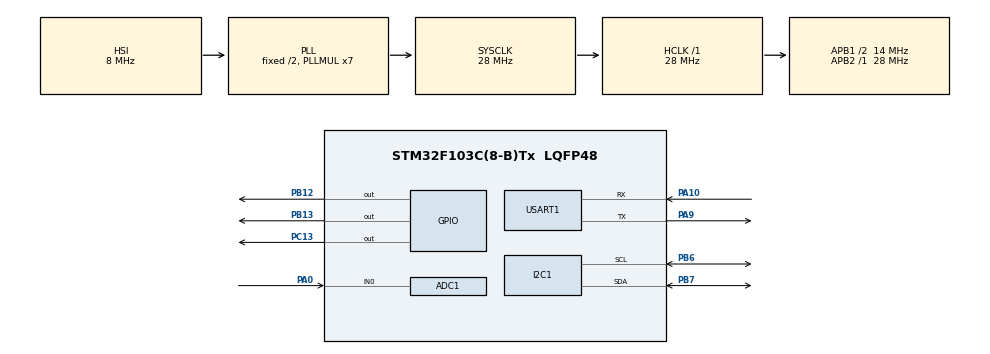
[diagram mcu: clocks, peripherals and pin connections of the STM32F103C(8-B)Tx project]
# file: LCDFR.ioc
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ADC1.Channel-2\#ChannelRegularConversion=ADC_CHANNEL_0
ADC1.NbrOfConversionFlag=1
ADC1.Rank-2\#ChannelRegularConversion=1
ADC1.SamplingTime-2\#ChannelRegularConversion=ADC_SAMPLETIME_239CYCLES_5
ADC1.master=1
Dma.ADC1.0.Direction=DMA_PERIPH_TO_MEMORY
Dma.ADC1.0.Instance=DMA1_Channel1
Dma.ADC1.0.MemDataAlignment=DMA_MDATAALIGN_WORD
Dma.ADC1.0.MemInc=DMA_MINC_ENABLE
Dma.ADC1.0.Mode=DMA_CIRCULAR
Dma.ADC1.0.PeriphDataAlignment=DMA_PDATAALIGN_WORD
Dma.ADC1.0.PeriphInc=DMA_PINC_DISABLE
Dma.ADC1.0.Priority=DMA_PRIORITY_LOW
Dma.Request0=ADC1
FREERTOS.Mutexes01=uartMutex,Dynamic,NULL
FREERTOS.Tasks01=TaskTemp,0,128,TaskTemp_init,Default,NULL,Dynamic,NULL,NULL;Task2,-3,128,Task2_init,Default,NULL,Dynamic,NULL,NULL
Mcu.Family=STM32F1
Mcu.Name=STM32F103C(8-B)Tx
Mcu.Package=LQFP48
NVIC.DMA1_Channel1_IRQn=true\:5\:0\:false\:false\:true\:true\:false\:true
NVIC.PriorityGroup=NVIC_PRIORITYGROUP_4
NVIC.TIM1_UP_IRQn=true\:0\:0\:false\:false\:true\:false\:false\:true
NVIC.TimeBase=TIM1_UP_IRQn
NVIC.TimeBaseIP=TIM1
PA0-WKUP.Signal=ADCx_IN0
PA10.Mode=Asynchronous
PA10.Signal=USART1_RX
PA13.Mode=Serial_Wire
PA13.Signal=SYS_JTMS-SWDIO
PA14.Mode=Serial_Wire
PA14.Signal=SYS_JTCK-SWCLK
PA9.Mode=Asynchronous
PA9.Signal=USART1_TX
PB12.Signal=GPIO_Output
PB13.Signal=GPIO_Output
PB6.Mode=I2C
PB6.Signal=I2C1_SCL
PB7.Mode=I2C
PB7.Signal=I2C1_SDA
PC13-TAMPER-RTC.Signal=GPIO_Output
ProjectManager.HeapSize=0x200
ProjectManager.StackSize=0x400
ProjectManager.TargetToolchain=STM32CubeIDE
RCC.AHBFreq_Value=28000000
RCC.APB1CLKDivider=RCC_HCLK_DIV2
RCC.APB1Freq_Value=14000000
RCC.APB1TimFreq_Value=28000000
RCC.APB2Freq_Value=28000000
RCC.APB2TimFreq_Value=28000000
RCC.HCLKFreq_Value=28000000
RCC.PLLMUL=RCC_PLL_MUL7
RCC.SYSCLKFreq_VALUE=28000000
RCC.SYSCLKSource=RCC_SYSCLKSOURCE_PLLCLK
RCC.USBFreq_Value=28000000
SH.ADCx_IN0.0=ADC1_IN0,IN0
USART1.VirtualMode=VM_ASYNC
VP_FREERTOS_VS_CMSIS_V1.Mode=CMSIS_V1
VP_SYS_VS_tim1.Mode=TIM1
board=custom

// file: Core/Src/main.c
/************************************************************************
* Copyright 2020 ITESM                                                  *
*                                                                       *
*                                                                       *
* Second Partial Project                                                *
*                                                                       *
* Authors:                                                              *
* Jesús Enrique Luna Medina          A01632334                          *
* Daniela abigail Parrales Mejía     A01228629                          *
* Luis Cortés Leal                   A01631163                          *
*                                                                       *
* May  2020                                                             *
*                                                                       *
* This is a temperature sensor that reports in serial port (UART)		*
* and in a 16x2 LCD I2C													*
*                                                                       *
************************************************************************/
#include "main.h"
#include "cmsis_os.h"

/* USER CODE BEGIN Includes */
#include "i2c-lcd.h"
/* USER CODE END Includes */

ADC_HandleTypeDef hadc1;
DMA_HandleTypeDef hdma_adc1;

I2C_HandleTypeDef hi2c1;

UART_HandleTypeDef huart1;

osThreadId TaskTempHandle;
osThreadId Task_ToggleHandle;
osMutexId uartMutexHandle;
osThreadId Task_LCDHandle;

void SystemClock_Config(void);
static void MX_GPIO_Init(void);
static void MX_DMA_Init(void);
static void MX_USART1_UART_Init(void);
static void MX_ADC1_Init(void);
static void MX_I2C1_Init(void);
void TaskTemp_init(void const * argument);
void Task_Toggle_init(void const * argument);
void Task_LCD_init(void const * argument);
void uart_Temp(void);

uint32_t value[1];
uint8_t data[]="Temp:    ,LEDMAX:    ,LEDMIN:    \r\n";

int main(void)
{

  SystemClock_Config();

  /* Initialize all configured peripherals */
  MX_GPIO_Init();
  MX_DMA_Init();
  MX_USART1_UART_Init();
  MX_ADC1_Init();
  MX_I2C1_Init();

  lcd_init();

  HAL_ADC_Start_DMA(&hadc1, value, 1);

  /* Create the mutex(es) */
  /* definition and creation of uartMutex */
  osMutexDef(uartMutex);
  uartMutexHandle = osMutexCreate(osMutex(uartMutex));

  /* Create the thread(s) */
  /* definition and creation of TaskTemp */
  osThreadDef(TaskTemp, TaskTemp_init, osPriorityNormal, 0, 128);
  TaskTempHandle = osThreadCreate(osThread(TaskTemp), NULL);

  /* definition and creation of Task_Toggle */
  osThreadDef(Task_Toggle, Task_Toggle_init, osPriorityNormal, 0, 128);
  Task_ToggleHandle = osThreadCreate(osThread(Task_Toggle), NULL);

  /* USER CODE BEGIN RTOS_THREADS */
  osThreadDef(Task_LCD, Task_LCD_init, osPriorityNormal, 0, 128);
  Task_LCDHandle = osThreadCreate(osThread(Task_LCD), NULL);
  /* USER CODE END RTOS_THREADS */

  /* Start scheduler */
  osKernelStart();

  while (1){

  }
}

void SystemClock_Config(void)
{
  RCC_OscInitTypeDef RCC_OscInitStruct = {0};
  RCC_ClkInitTypeDef RCC_ClkInitStruct = {0};
  RCC_PeriphCLKInitTypeDef PeriphClkInit = {0};

  /** Initializes the CPU, AHB and APB busses clocks
  */
  RCC_OscInitStruct.OscillatorType = RCC_OSCILLATORTYPE_HSI;
  RCC_OscInitStruct.HSIState = RCC_HSI_ON;
  RCC_OscInitStruct.HSICalibrationValue = RCC_HSICALIBRATION_DEFAULT;
  RCC_OscInitStruct.PLL.PLLState = RCC_PLL_ON;
  RCC_OscInitStruct.PLL.PLLSource = RCC_PLLSOURCE_HSI_DIV2;
  RCC_OscInitStruct.PLL.PLLMUL = RCC_PLL_MUL7;
  if (HAL_RCC_OscConfig(&RCC_OscInitStruct) != HAL_OK)
  {
    Error_Handler();
  }
  /** Initializes the CPU, AHB and APB busses clocks
  */
  RCC_ClkInitStruct.ClockType = RCC_CLOCKTYPE_HCLK|RCC_CLOCKTYPE_SYSCLK
                              |RCC_CLOCKTYPE_PCLK1|RCC_CLOCKTYPE_PCLK2;
  RCC_ClkInitStruct.SYSCLKSource = RCC_SYSCLKSOURCE_PLLCLK;
  RCC_ClkInitStruct.AHBCLKDivider = RCC_SYSCLK_DIV1;
  RCC_ClkInitStruct.APB1CLKDivider = RCC_HCLK_DIV2;
  RCC_ClkInitStruct.APB2CLKDivider = RCC_HCLK_DIV1;

  if (HAL_RCC_ClockConfig(&RCC_ClkInitStruct, FLASH_LATENCY_1) != HAL_OK)
  {
    Error_Handler();
  }
  PeriphClkInit.PeriphClockSelection = RCC_PERIPHCLK_ADC;
  PeriphClkInit.AdcClockSelection = RCC_ADCPCLK2_DIV2;
  if (HAL_RCCEx_PeriphCLKConfig(&PeriphClkInit) != HAL_OK)
  {
    Error_Handler();
  }
}

static void MX_ADC1_Init(void)
{
  ADC_ChannelConfTypeDef sConfig = {0};

  /* USER CODE END ADC1_Init 1 */
  /** Common config
  */
  hadc1.Instance = ADC1;
  hadc1.Init.ScanConvMode = ADC_SCAN_DISABLE;
  hadc1.Init.ContinuousConvMode = DISABLE;
  hadc1.Init.DiscontinuousConvMode = DISABLE;
  hadc1.Init.ExternalTrigConv = ADC_SOFTWARE_START;
  hadc1.Init.DataAlign = ADC_DATAALIGN_RIGHT;
  hadc1.Init.NbrOfConversion = 1;
  if (HAL_ADC_Init(&hadc1) != HAL_OK)
  {
    Error_Handler();
  }
  /** Configure Regular Channel
  */
  sConfig.Channel = ADC_CHANNEL_0;
  sConfig.Rank = ADC_REGULAR_RANK_1;
  sConfig.SamplingTime = ADC_SAMPLETIME_239CYCLES_5;
  if (HAL_ADC_ConfigChannel(&hadc1, &sConfig) != HAL_OK)
  {
    Error_Handler();
  }
}

static void MX_I2C1_Init(void)
{

  hi2c1.Instance = I2C1;
  hi2c1.Init.ClockSpeed = 100000;
  hi2c1.Init.DutyCycle = I2C_DUTYCYCLE_2;
  hi2c1.Init.OwnAddress1 = 0;
  hi2c1.Init.AddressingMode = I2C_ADDRESSINGMODE_7BIT;
  hi2c1.Init.DualAddressMode = I2C_DUALADDRESS_DISABLE;
  hi2c1.Init.OwnAddress2 = 0;
  hi2c1.Init.GeneralCallMode = I2C_GENERALCALL_DISABLE;
  hi2c1.Init.NoStretchMode = I2C_NOSTRETCH_DISABLE;
  if (HAL_I2C_Init(&hi2c1) != HAL_OK)
  {
    Error_Handler();
  }
}

static void MX_USART1_UART_Init(void)
{
  huart1.Instance = USART1;
  huart1.Init.BaudRate = 115200;
  huart1.Init.WordLength = UART_WORDLENGTH_8B;
  huart1.Init.StopBits = UART_STOPBITS_1;
  huart1.Init.Parity = UART_PARITY_NONE;
  huart1.Init.Mode = UART_MODE_TX_RX;
  huart1.Init.HwFlowCtl = UART_HWCONTROL_NONE;
  huart1.Init.OverSampling = UART_OVERSAMPLING_16;
  if (HAL_UART_Init(&huart1) != HAL_OK)
  {
    Error_Handler();
  }
}

static void MX_DMA_Init(void)
{

  /* DMA controller clock enable */
  __HAL_RCC_DMA1_CLK_ENABLE();

  /* DMA interrupt init */
  /* DMA1_Channel1_IRQn interrupt configuration */
  HAL_NVIC_SetPriority(DMA1_Channel1_IRQn, 5, 0);
  HAL_NVIC_EnableIRQ(DMA1_Channel1_IRQn);

}

static void MX_GPIO_Init(void)
{
  GPIO_InitTypeDef GPIO_InitStruct = {0};

  /* GPIO Ports Clock Enable */
  __HAL_RCC_GPIOC_CLK_ENABLE();
  __HAL_RCC_GPIOA_CLK_ENABLE();
  __HAL_RCC_GPIOB_CLK_ENABLE();

  /*Configure GPIO pin Output Level */
  HAL_GPIO_WritePin(GPIOC, GPIO_PIN_13, GPIO_PIN_SET);

  /*Configure GPIO pin Output Level */
  HAL_GPIO_WritePin(GPIOB, GPIO_PIN_12|GPIO_PIN_13, GPIO_PIN_SET);

  /*Configure GPIO pin : PC13 */
  GPIO_InitStruct.Pin = GPIO_PIN_13;
  GPIO_InitStruct.Mode = GPIO_MODE_OUTPUT_PP;
  GPIO_InitStruct.Pull = GPIO_NOPULL;
  GPIO_InitStruct.Speed = GPIO_SPEED_FREQ_LOW;
  HAL_GPIO_Init(GPIOC, &GPIO_InitStruct);

  /*Configure GPIO pins : PB12 PB13 */
  GPIO_InitStruct.Pin = GPIO_PIN_12|GPIO_PIN_13;
  GPIO_InitStruct.Mode = GPIO_MODE_OUTPUT_PP;
  GPIO_InitStruct.Pull = GPIO_NOPULL;
  GPIO_InitStruct.Speed = GPIO_SPEED_FREQ_LOW;
  HAL_GPIO_Init(GPIOB, &GPIO_InitStruct);

}

/* USER CODE END Header_TaskTemp_init */
void TaskTemp_init(void const * argument)
{
  for(;;)
  {
	HAL_ADC_Start_DMA(&hadc1, value, 1);
	osDelay(500);

	xSemaphoreTake(uartMutexHandle, portMAX_DELAY);
	HAL_UART_Transmit(&huart1, data, 35 ,1000);
	xSemaphoreGive(uartMutexHandle);
    osDelay(500);//cada seg
  }
}

void Task_Toggle_init(void const * argument)
{
  for(;;)
  {
	 xSemaphoreTake(uartMutexHandle, portMAX_DELAY);
	 HAL_GPIO_TogglePin(GPIOC, GPIO_PIN_13);
	 xSemaphoreGive(uartMutexHandle);
    osDelay(500); /* !< Every second */
  }
}

void Task_LCD_init(void const * argument)
{
  for(;;)
  {
	lcd_send_cmd(0x80);
	  lcd_send_string("TEMP:");
	  lcd_send_data((value[0]/1000)+48);          /* !< decimal */
	  lcd_send_data(((value[0]%1000)/100)+48);    /* !< unit */
	  lcd_send_string(".");
	  lcd_send_data(((value[0]%100)/10)+48);      /* !< decimal point */
	  lcd_send_string(" C     ");
	  lcd_send_cmd(0xc0);                         /* !< second line */
	  lcd_send_string("                ");

	  HAL_Delay(200);

	  /* !< LED conditional indicators*/
	  	  if(((value[0]/1000)+48)>50){
			  HAL_GPIO_WritePin(GPIOB, GPIO_PIN_13, GPIO_PIN_RESET);    /* !< ON */
			  HAL_GPIO_WritePin(GPIOB, GPIO_PIN_12, GPIO_PIN_SET);      /* !< OFF */
			  data[18]='O', data[19]='n', data[20]=' ';
			  data[30]='O', data[31]='f', data[32]='f';
	  	  }

	  	  if(((value[0]/1000)+48)<50){
	  		  HAL_GPIO_WritePin(GPIOB, GPIO_PIN_13, GPIO_PIN_SET);    /* !< OFF */
			  HAL_GPIO_WritePin(GPIOB, GPIO_PIN_12, GPIO_PIN_RESET);    /* !< ON */
			  data[18]='O', data[19]='f', data[20]='f';
			  data[30]='O', data[31]='n', data[32]=' ';
	  	  }
	  	  if(((value[0]/1000)+48) == 50){
	  		  HAL_GPIO_WritePin(GPIOB, GPIO_PIN_13, GPIO_PIN_SET);    /* !< OFF */
	  		  HAL_GPIO_WritePin(GPIOB, GPIO_PIN_12, GPIO_PIN_SET);    /* !< ON */
	  		  data[18]='O', data[19]='f', data[20]='f';
	  		  data[30]='O', data[31]='f', data[32]='f';
	  	  }

	  	/* !< Print temp in uart */
	  	uart_Temp();

    osDelay(1000); /* !< Every second */
  }
}

 /**
  * @brief  Period elapsed callback in non blocking mode
  * @note   This function is called  when TIM1 interrupt took place, inside
  * HAL_TIM_IRQHandler(). It makes a direct call to HAL_IncTick() to increment
  * a global variable "uwTick" used as application time base.
  * @param  htim : TIM handle
  * @retval None
  */
void uart_Temp(void){
	  data[6]=((value[0]/1000)+48);
	  data[7]=(((value[0]%1000)/100)+48);
	  data[8]=('C');
}

void HAL_TIM_PeriodElapsedCallback(TIM_HandleTypeDef *htim)
{
  if (htim->Instance == TIM1) {
    HAL_IncTick();
  }
}

void Error_Handler(void)
{
}

/************************ (C) COPYRIGHT STMicroelectronics *****END OF FILE****/
